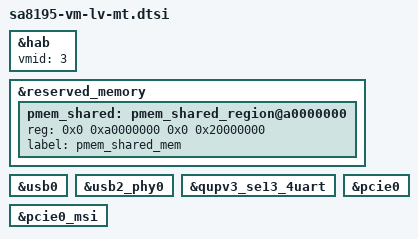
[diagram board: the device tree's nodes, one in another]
/ {
	/delete-node/ cpus;
};

&hab {
	vmid = <3>;
};

&reserved_memory {
	pmem_shared: pmem_shared_region@a0000000 {
		reg = <0x0 0xa0000000 0x0 0x20000000>;
		label = "pmem_shared_mem";
	};
};

&usb0 {
	status = "ok";
};

&usb2_phy0 {
	status = "ok";
};

&qupv3_se13_4uart {
	status = "ok";
};

&pcie0_msi {
	status = "ok";
};

&pcie0 {
	status = "ok";
};
